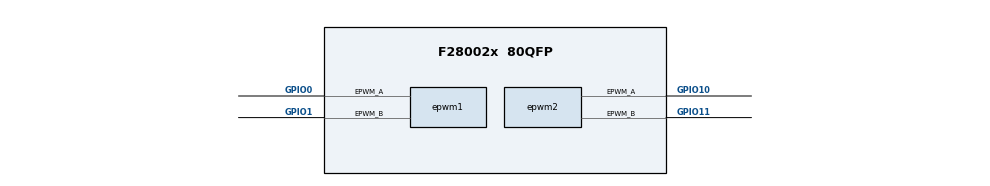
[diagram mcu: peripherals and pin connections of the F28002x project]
/**
 * @cliArgs --device "F28002x" --package "80QFP" --part "F28002x_80QFP" --product "C2000WARE@3.01.00.00"
 * @versions {"tool":"1.10.0+2029"}
 */

/**
 * Import the modules used in this configuration.
 */
const clb                              = scripting.addModule("/driverlib/clb.js", {}, false);
const clb1                             = clb.addInstance();
const clb2                             = clb.addInstance();
const epwm                             = scripting.addModule("/driverlib/epwm.js", {}, false);
const epwm1                            = epwm.addInstance();
const epwm2                            = epwm.addInstance();
const TILE                             = scripting.addModule("/utilities/clb_tool/clb_syscfg/source/TILE");
const TILE1                            = TILE.addInstance();
const TILE2                            = TILE.addInstance();
const clb_run_dynamic_template_clb_c   = scripting.addModule("/utilities/clb_tool/clb_syscfg/source/clb_run_dynamic_template_clb_c.js");
const clb_run_dynamic_template_clb_dot = scripting.addModule("/utilities/clb_tool/clb_syscfg/source/clb_run_dynamic_template_clb_dot.js");
const clb_run_dynamic_template_clb_h   = scripting.addModule("/utilities/clb_tool/clb_syscfg/source/clb_run_dynamic_template_clb_h.js");
const clb_run_dynamic_template_clb_sim = scripting.addModule("/utilities/clb_tool/clb_syscfg/source/clb_run_dynamic_template_clb_sim.js");

/**
 * Write custom configuration values to the imported modules.
 */
clb1.$name               = "myTILE1";
clb1.enableCLB           = true;
clb1.inputsUsed          = ["CLB_IN0","CLB_IN1","CLB_IN2","CLB_IN3"];
clb1.inputTypeCLB_IN0    = "GLOBAL";
clb1.inputTypeCLB_IN1    = "GLOBAL";
clb1.inputTypeCLB_IN2    = "GLOBAL";
clb1.inputTypeCLB_IN3    = "GLOBAL";
clb1.globalConfigCLB_IN2 = "CLB_GLOBAL_IN_MUX_EPWM1B";
clb1.globalConfigCLB_IN3 = "CLB_GLOBAL_IN_MUX_EPWM1B";
clb1.filterConfigCLB_IN0 = "CLB_FILTER_FALLING_EDGE";
clb1.filterConfigCLB_IN2 = "CLB_FILTER_FALLING_EDGE";

clb2.clbBase             = "CLB2_BASE";
clb2.$name               = "myTILE2";
clb2.enableCLB           = true;
clb2.inputsUsed          = ["CLB_IN0","CLB_IN1","CLB_IN2","CLB_IN3"];
clb2.inputTypeCLB_IN0    = "GLOBAL";
clb2.inputTypeCLB_IN1    = "GLOBAL";
clb2.inputTypeCLB_IN2    = "GLOBAL";
clb2.inputTypeCLB_IN3    = "GLOBAL";
clb2.filterConfigCLB_IN0 = "CLB_FILTER_FALLING_EDGE";
clb2.filterConfigCLB_IN2 = "CLB_FILTER_FALLING_EDGE";
clb2.globalConfigCLB_IN1 = "CLB_GLOBAL_IN_MUX_EPWM6A";
clb2.globalConfigCLB_IN2 = "CLB_GLOBAL_IN_MUX_EPWM6B";
clb2.globalConfigCLB_IN3 = "CLB_GLOBAL_IN_MUX_EPWM6B";
clb2.globalConfigCLB_IN0 = "CLB_GLOBAL_IN_MUX_EPWM6A";

epwm1.$name                  = "myEPWM1";
epwm1.epwm.$assign           = "EPWM1";
epwm1.epwm.epwm_aPin.$assign = "GPIO0";
epwm1.epwm.epwm_bPin.$assign = "GPIO1";

epwm2.$name                  = "myEPWM2";
epwm2.epwm.$assign           = "EPWM6";
epwm2.epwm.epwm_aPin.$assign = "GPIO10";
epwm2.epwm.epwm_bPin.$assign = "GPIO11";

TILE.sim_duration = 500000000;

TILE1.$name                  = "TILE1";
TILE1.BOUNDARY.$name         = "BOUNDARY0";
TILE1.BOUNDARY.boundaryInput0           = "squareWave";
TILE1.BOUNDARY.boundaryInput1           = "squareWave";
TILE1.BOUNDARY.boundaryInput2           = "squareWave";
TILE1.BOUNDARY.boundaryInput3           = "squareWave";
TILE1.BOUNDARY.in_edge2      = "falling edge";
TILE1.BOUNDARY.in_edge0      = "falling edge";
TILE1.BOUNDARY.in_period0    = 1000;
TILE1.BOUNDARY.in_duty0      = 500;
TILE1.BOUNDARY.in_period1    = 1000;
TILE1.BOUNDARY.in_duty1      = 500;
TILE1.BOUNDARY.in_period2    = 500;
TILE1.BOUNDARY.in_duty2      = 250;
TILE1.BOUNDARY.in_period3    = 500;
TILE1.BOUNDARY.in_duty3      = 250;
TILE1.LUT_0.$name            = "LUT_0";
TILE1.LUT_1.$name            = "LUT_1";
TILE1.LUT_1.i0               = "FSM_0.S0";
TILE1.LUT_1.eqn              = "~(i0 | i1)";
TILE1.LUT_1.i1               = "BOUNDARY.in0";
TILE1.LUT_2.$name            = "LUT_2";
TILE1.LUT_2.i0               = "FSM_1.S0";
TILE1.LUT_2.eqn              = "~(i0 | i1)";
TILE1.LUT_2.i1               = "BOUNDARY.in2";
TILE1.FSM_0.$name            = "FSM_0";
TILE1.FSM_0.e1               = "COUNTER_0.count_match1";
TILE1.FSM_0.eqn_out          = "~s0";
TILE1.FSM_0.e0               = "BOUNDARY.in0";
TILE1.FSM_0.eqn_s0           = "(~s0 & e0) | (s0 & (~e1)) ";
TILE1.FSM_1.$name            = "FSM_1";
TILE1.FSM_1.e1               = "COUNTER_1.count_match1";
TILE1.FSM_1.eqn_s0           = "(~s0 & e0) | (s0 & (~e1)) ";
TILE1.FSM_1.eqn_out          = "~s0";
TILE1.FSM_1.e0               = "BOUNDARY.in2";
TILE1.FSM_2.$name            = "FSM_2";
TILE1.COUNTER_0.$name        = "COUNTER_0";
TILE1.COUNTER_0.reset        = "FSM_0.OUT";
TILE1.COUNTER_0.mode1        = "1";
TILE1.COUNTER_0.match1_val   = "10";
TILE1.COUNTER_0.mode0        = "FSM_0.S0";
TILE1.COUNTER_1.$name        = "COUNTER_1";
TILE1.COUNTER_1.reset        = "FSM_1.OUT";
TILE1.COUNTER_1.mode0        = "FSM_1.S0";
TILE1.COUNTER_1.match1_val   = "10";
TILE1.COUNTER_1.mode1        = "1";
TILE1.COUNTER_2.$name        = "COUNTER_2";
TILE1.OUTLUT_0.$name         = "OUTLUT_0";
TILE1.OUTLUT_0.i1            = "BOUNDARY.in1";
TILE1.OUTLUT_0.i0            = "LUT_2.OUT";
TILE1.OUTLUT_0.i2            = "BOUNDARY.in3";
TILE1.OUTLUT_0.eqn           = "i0 & (~(i1 & i2)) & i1";
TILE1.OUTLUT_1.$name         = "OUTLUT_1";
TILE1.OUTLUT_2.$name         = "OUTLUT_2";
TILE1.OUTLUT_2.i1            = "BOUNDARY.in3";
TILE1.OUTLUT_2.i0            = "LUT_1.OUT";
TILE1.OUTLUT_2.i2            = "BOUNDARY.in1";
TILE1.OUTLUT_2.eqn           = "i0 & (~(i1 & i2)) & i1";
TILE1.OUTLUT_3.$name         = "OUTLUT_3";
TILE1.OUTLUT_3.eqn           = "0";
TILE1.OUTLUT_4.$name         = "OUTLUT_4";
TILE1.OUTLUT_5.$name         = "OUTLUT_5";
TILE1.OUTLUT_6.$name         = "OUTLUT_6";
TILE1.OUTLUT_7.$name         = "OUTLUT_7";
TILE1.HLC.$name              = "HLC_0";
TILE1.HLC.program0.$name     = "HLCP_0";
TILE1.HLC.program1.$name     = "HLCP_1";
TILE1.HLC.program2.$name     = "HLCP_2";
TILE1.HLC.program2.instruct0 = "mov r0,c0";
TILE1.HLC.program3.$name     = "HLCP_3";
TILE1.AOC_0.$name            = "AOC_0";
TILE1.AOC_1.$name            = "AOC_1";
TILE1.AOC_2.$name            = "AOC_2";
TILE1.AOC_3.$name            = "AOC_3";
TILE1.AOC_4.$name            = "AOC_4";
TILE1.AOC_5.$name            = "AOC_5";
TILE1.AOC_6.$name            = "AOC_6";
TILE1.AOC_7.$name            = "AOC_7";

TILE2.$name                = "TILE2";
TILE2.BOUNDARY.$name       = "BOUNDARY1";
TILE2.LUT_0.$name          = "LUT_3";
TILE2.LUT_1.$name          = "LUT_4";
TILE2.LUT_1.eqn            = "~(i0 | i1)";
TILE2.LUT_1.i0             = "FSM_0.S0";
TILE2.LUT_1.i1             = "BOUNDARY.in0";
TILE2.LUT_2.$name          = "LUT_5";
TILE2.LUT_2.eqn            = "~(i0 | i1)";
TILE2.LUT_2.i1             = "BOUNDARY.in2";
TILE2.LUT_2.i0             = "FSM_1.S0";
TILE2.FSM_0.$name          = "FSM_3";
TILE2.FSM_0.eqn_out        = "~s0";
TILE2.FSM_0.e0             = "BOUNDARY.in0";
TILE2.FSM_0.e1             = "COUNTER_0.count_match1";
TILE2.FSM_0.eqn_s0         = "(~s0 & e0) | (s0 & (~e1)) ";
TILE2.FSM_1.$name          = "FSM_4";
TILE2.FSM_1.eqn_s0         = "(~s0 & e0) | (s0 & (~e1)) ";
TILE2.FSM_1.eqn_out        = "~s0";
TILE2.FSM_1.e0             = "BOUNDARY.in2";
TILE2.FSM_1.e1             = "COUNTER_1.count_match1";
TILE2.FSM_2.$name          = "FSM_5";
TILE2.COUNTER_0.$name      = "COUNTER_3";
TILE2.COUNTER_0.reset      = "FSM_0.OUT";
TILE2.COUNTER_0.mode0      = "FSM_0.S0";
TILE2.COUNTER_0.mode1      = "1";
TILE2.COUNTER_0.match1_val = "10";
TILE2.COUNTER_1.$name      = "COUNTER_4";
TILE2.COUNTER_1.reset      = "FSM_1.OUT";
TILE2.COUNTER_1.mode0      = "FSM_1.S0";
TILE2.COUNTER_1.mode1      = "1";
TILE2.COUNTER_1.match1_val = "10";
TILE2.COUNTER_2.$name      = "COUNTER_5";
TILE2.OUTLUT_0.$name       = "OUTLUT_8";
TILE2.OUTLUT_0.eqn         = "i0 & (~(i1 & i2)) & i1";
TILE2.OUTLUT_0.i0          = "LUT_2.OUT";
TILE2.OUTLUT_0.i1          = "BOUNDARY.in1";
TILE2.OUTLUT_0.i2          = "BOUNDARY.in3";
TILE2.OUTLUT_1.$name       = "OUTLUT_9";
TILE2.OUTLUT_2.$name       = "OUTLUT_10";
TILE2.OUTLUT_2.eqn         = "i0 & (~(i1 & i2)) & i1";
TILE2.OUTLUT_2.i0          = "LUT_1.OUT";
TILE2.OUTLUT_2.i1          = "BOUNDARY.in3";
TILE2.OUTLUT_2.i2          = "BOUNDARY.in1";
TILE2.OUTLUT_3.$name       = "OUTLUT_11";
TILE2.OUTLUT_4.$name       = "OUTLUT_12";
TILE2.OUTLUT_5.$name       = "OUTLUT_13";
TILE2.OUTLUT_6.$name       = "OUTLUT_14";
TILE2.OUTLUT_7.$name       = "OUTLUT_15";
TILE2.HLC.$name            = "HLC_1";
TILE2.HLC.program0.$name   = "HLCP_4";
TILE2.HLC.program1.$name   = "HLCP_5";
TILE2.HLC.program2.$name   = "HLCP_6";
TILE2.HLC.program3.$name   = "HLCP_7";
TILE2.AOC_0.$name          = "AOC_8";
TILE2.AOC_1.$name          = "AOC_9";
TILE2.AOC_2.$name          = "AOC_10";
TILE2.AOC_3.$name          = "AOC_11";
TILE2.AOC_4.$name          = "AOC_12";
TILE2.AOC_5.$name          = "AOC_13";
TILE2.AOC_6.$name          = "AOC_14";
TILE2.AOC_7.$name          = "AOC_15";
